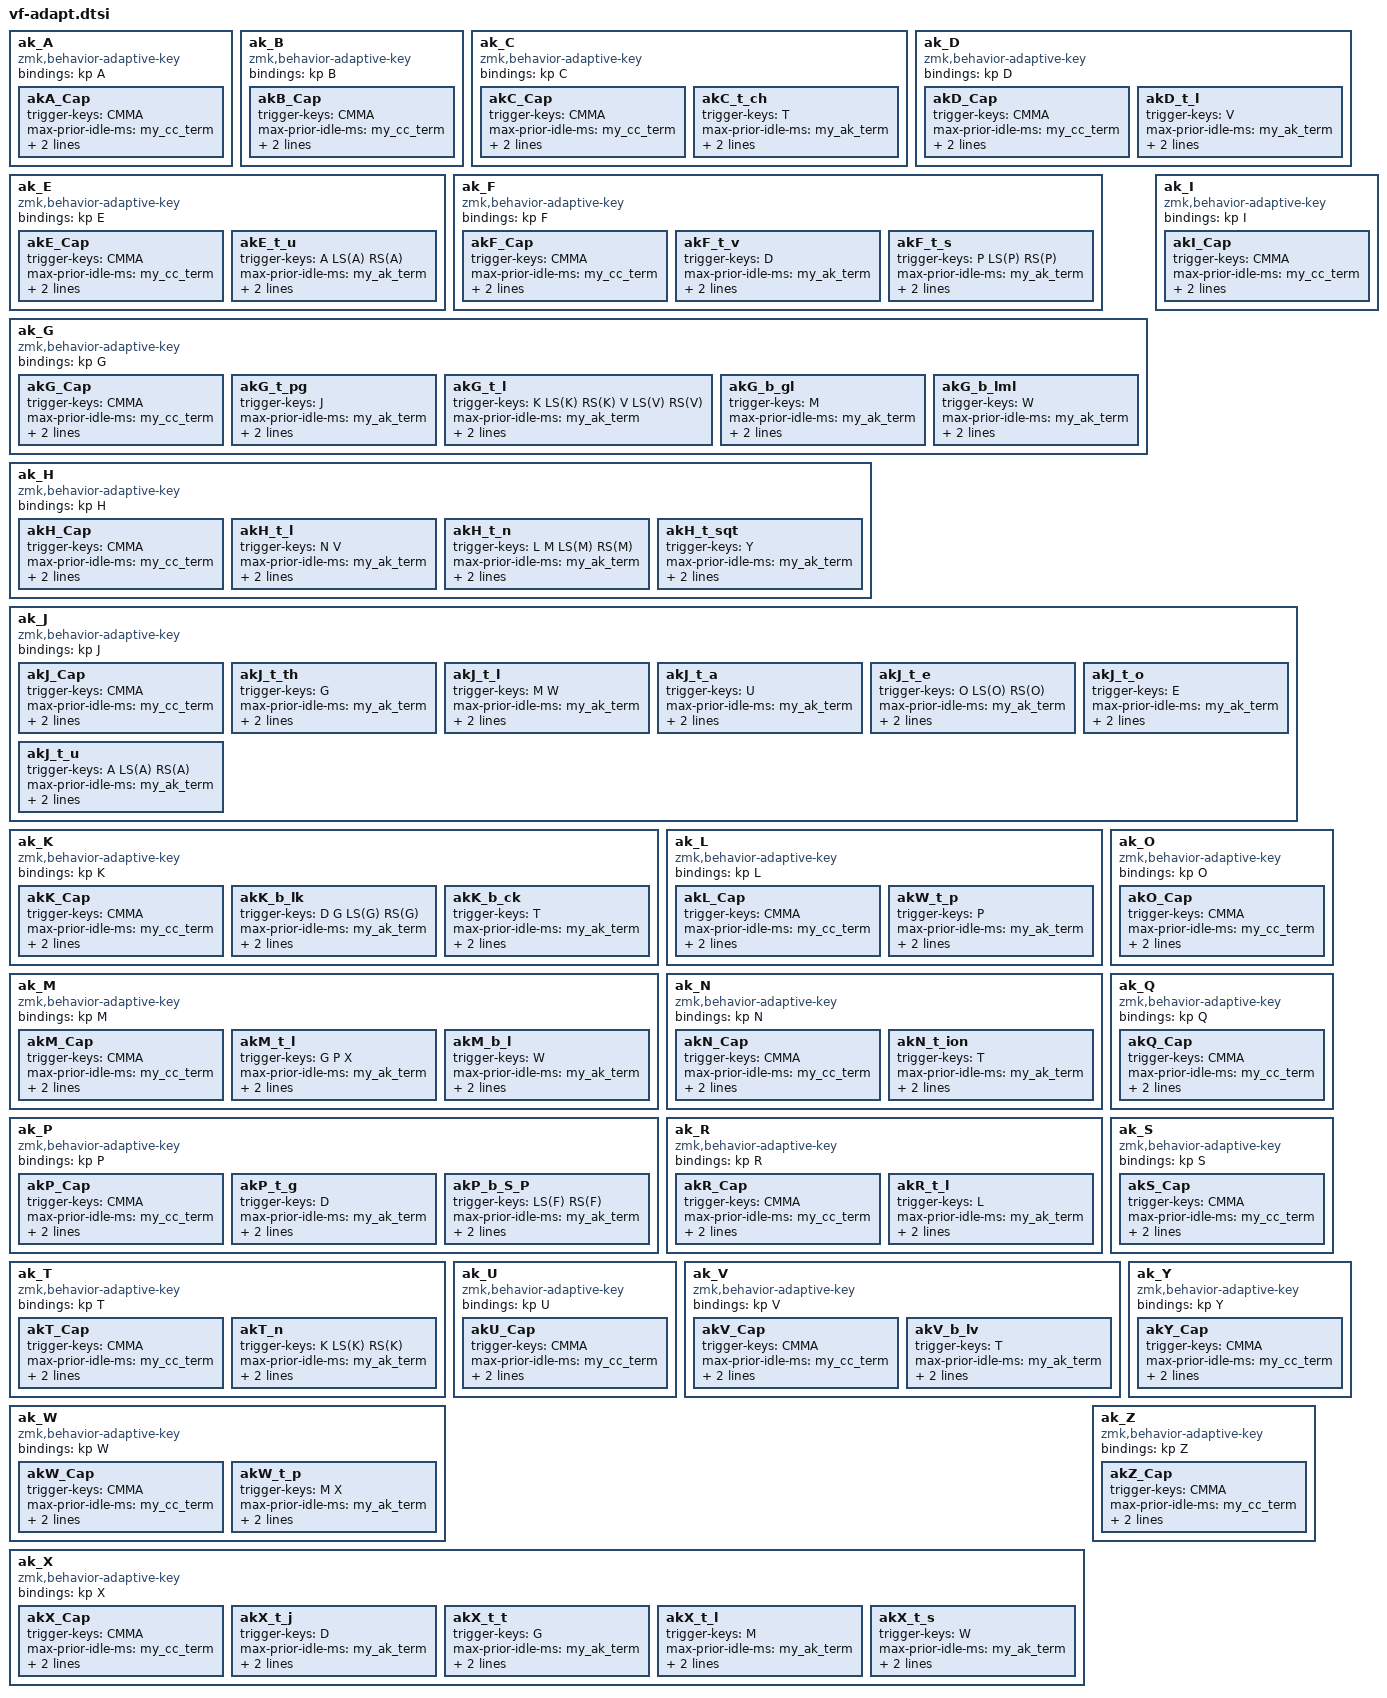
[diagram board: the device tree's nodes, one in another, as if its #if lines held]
/*
 * vf-adapt.h
 *
 * SPDX-License-Identifier: MIT
 *
 * AdaptiveKey behaviors
 * (send a different behavior based on prior key)
 *
 * these rules are very dependant on the underlying alpha layout topography
 *
 * using urob's behavior-adaptive-key module (https://github.com/urob/zmk-adaptive-key/)
 *
 */
 
        ak_A: ak_A {
            compatible = "zmk,behavior-adaptive-key";
            #binding-cells = <0>;
            bindings = <&kp A>;

            akA_Cap { trigger-keys = <CMMA>; max-prior-idle-ms = <my_cc_term>; bindings = <&kp BSPC &kp LS(A)>; strict-modifiers; };
        };
        ak_B: ak_B {
            compatible = "zmk,behavior-adaptive-key";
            #binding-cells = <0>;
            bindings = <&kp B>;

            akB_Cap { trigger-keys = <CMMA>; max-prior-idle-ms = <my_cc_term>; bindings = <&kp BSPC &kp LS(B)>; strict-modifiers; };
        };
        ak_C: ak_C {
            compatible = "zmk,behavior-adaptive-key";
            #binding-cells = <0>;
            bindings = <&kp C>;

            akC_Cap { trigger-keys = <CMMA>; max-prior-idle-ms = <my_cc_term>; bindings = <&kp BSPC &kp LS(C)>; strict-modifiers; };
            akC_t_ch { trigger-keys = <T>; max-prior-idle-ms = <my_ak_term>; bindings = <&kp C &kp H>; strict-modifiers; };
        };
        ak_D: ak_D {
            compatible = "zmk,behavior-adaptive-key";
            #binding-cells = <0>;
            bindings = <&kp D>;

            akD_Cap { trigger-keys = <CMMA>; max-prior-idle-ms = <my_cc_term>; bindings = <&kp BSPC &kp LS(D)>; strict-modifiers; };
            akD_t_l { trigger-keys = <V>; max-prior-idle-ms = <my_ak_term>; bindings = <&kp L>; strict-modifiers; };
        };
        ak_E: ak_E {
            compatible = "zmk,behavior-adaptive-key";
            #binding-cells = <0>;
            bindings = <&kp E>;

            akE_Cap { trigger-keys = <CMMA>; max-prior-idle-ms = <my_cc_term>; bindings = <&kp BSPC &kp LS(E)>; strict-modifiers; };
#ifdef MagicJ
            akE_t_u { trigger-keys = <A LS(A) RS(A)>; max-prior-idle-ms = <my_ak_term>; bindings = <&kp U>; strict-modifiers; };
#endif // MagicJ
        };
        ak_F: ak_F {
            compatible = "zmk,behavior-adaptive-key";
            #binding-cells = <0>;
            bindings = <&kp F>;

            akF_Cap { trigger-keys = <CMMA>; max-prior-idle-ms = <my_cc_term>; bindings = <&kp BSPC &kp LS(F)>; strict-modifiers; };
            akF_t_v { trigger-keys = <D>; max-prior-idle-ms = <my_ak_term>; bindings = <&kp V>; strict-modifiers; };
            akF_t_s { trigger-keys = <P LS(P) RS(P)>; max-prior-idle-ms = <my_ak_term>; bindings = <&kp S>; strict-modifiers; };
        };
        ak_G: ak_G {
            compatible = "zmk,behavior-adaptive-key";
            #binding-cells = <0>;
            bindings = <&kp G>;

            akG_Cap { trigger-keys = <CMMA>; max-prior-idle-ms = <my_cc_term>; bindings = <&kp BSPC &kp LS(G)>; strict-modifiers; };
            akG_t_pg { trigger-keys = <J>; max-prior-idle-ms = <my_ak_term>; bindings = <&kp P &kp G>; strict-modifiers; };
            akG_t_l  { trigger-keys = <K LS(K) RS(K) V LS(V) RS(V)>; max-prior-idle-ms = <my_ak_term>; bindings = <&kp L>; strict-modifiers; };
            akG_b_gl { trigger-keys = <M>; max-prior-idle-ms = <my_ak_term>; bindings = <&kp BSPC &kp L &kp G>; strict-modifiers; };
            akG_b_lml { trigger-keys = <W>; max-prior-idle-ms = <my_ak_term>; bindings = <&kp BSPC &kp L &kp M &kp L>; strict-modifiers; };
        };
        ak_H: ak_H {
            compatible = "zmk,behavior-adaptive-key";
            #binding-cells = <0>;
            bindings = <&kp H>;

            akH_Cap { trigger-keys = <CMMA>; max-prior-idle-ms = <my_cc_term>; bindings = <&kp BSPC &kp LS(H)>; strict-modifiers; };
            akH_t_l { trigger-keys = <N V>; max-prior-idle-ms = <my_ak_term>; bindings = <&kp L>; strict-modifiers; };
            akH_t_n { trigger-keys = <L M LS(M) RS(M)>; max-prior-idle-ms = <my_ak_term>; bindings = <&kp N>; strict-modifiers; };
            akH_t_sqt { trigger-keys = <Y>; max-prior-idle-ms = <my_ak_term>; bindings = <&kp SQT>; strict-modifiers; };
#ifdef MagicH
//            akH_t_a { trigger-keys = <U LS(U) RS(U)>; max-prior-idle-ms = <my_ak_term>; bindings = <&kp A>; strict-modifiers; };
//            akH_t_e { trigger-keys = <O LS(O) RS(O)>; max-prior-idle-ms = <my_ak_term>; bindings = <&kp E>; strict-modifiers; };
//            akH_t_o { trigger-keys = <E LS(E) RS(E)>; max-prior-idle-ms = <my_ak_term>; bindings = <&kp O>; strict-modifiers; };
//            akH_t_u { trigger-keys = <A LS(A) RS(A)>; max-prior-idle-ms = <my_ak_term>; bindings = <&kp U>; strict-modifiers; };
#endif // MagicH
        };
        ak_I: ak_I {
            compatible = "zmk,behavior-adaptive-key";
            #binding-cells = <0>;
            bindings = <&kp I>;

            akI_Cap { trigger-keys = <CMMA>; max-prior-idle-ms = <my_cc_term>; bindings = <&kp BSPC &kp LS(I)>; strict-modifiers; };
        };
        ak_J: ak_J {
            compatible = "zmk,behavior-adaptive-key";
            #binding-cells = <0>;
            bindings = <&kp J>;

            akJ_Cap { trigger-keys = <CMMA>; max-prior-idle-ms = <my_cc_term>; bindings = <&kp BSPC &kp LS(J)>; strict-modifiers; };
            akJ_t_th { trigger-keys = <G>; max-prior-idle-ms = <my_ak_term>; bindings = <&kp T &kp H>; strict-modifiers; strict-modifiers; };
            akJ_t_l { trigger-keys = <M W>; max-prior-idle-ms = <my_ak_term>; bindings = <&kp L>; strict-modifiers; strict-modifiers; };
/*
 * explore using J as a magic key like H for the four vowel SFBs
 *
 */
            akJ_t_a { trigger-keys = <U>; max-prior-idle-ms = <my_ak_term>; bindings = <&kp A>; strict-modifiers; strict-modifiers; };
            akJ_t_e { trigger-keys = <O LS(O) RS(O)>; max-prior-idle-ms = <my_ak_term>; bindings = <&kp E>; strict-modifiers; strict-modifiers; };
            akJ_t_o { trigger-keys = <E>; max-prior-idle-ms = <my_ak_term>; bindings = <&kp O>; strict-modifiers; strict-modifiers; };
            akJ_t_u { trigger-keys = <A LS(A) RS(A)>; max-prior-idle-ms = <my_ak_term>; bindings = <&kp U>; strict-modifiers; strict-modifiers; };

        };
        ak_K: ak_K {
            compatible = "zmk,behavior-adaptive-key";
            #binding-cells = <0>;
            bindings = <&kp K>;

            akK_Cap { trigger-keys = <CMMA>; max-prior-idle-ms = <my_cc_term>; bindings = <&kp BSPC &kp LS(K)>; strict-modifiers; };
            akK_b_lk { trigger-keys = <D G LS(G) RS(G)>; max-prior-idle-ms = <my_ak_term>; bindings = <&kp BSPC &kp L &kp K>; strict-modifiers; };
            akK_b_ck { trigger-keys = <T>; max-prior-idle-ms = <my_ak_term>; bindings = <&kp BSPC &kp C &kp K>; strict-modifiers; };
        };
        ak_L: ak_L {
            compatible = "zmk,behavior-adaptive-key";
            #binding-cells = <0>;
            bindings = <&kp L>;

            akL_Cap { trigger-keys = <CMMA>; max-prior-idle-ms = <my_cc_term>; bindings = <&kp BSPC &kp LS(L)>; strict-modifiers; };
            akW_t_p { trigger-keys = <P>; max-prior-idle-ms = <my_ak_term>; bindings = <&sl_L>; strict-modifiers; };
        };
        ak_M: ak_M {
            compatible = "zmk,behavior-adaptive-key";
            #binding-cells = <0>;
            bindings = <&kp M>;

            akM_Cap { trigger-keys = <CMMA>; max-prior-idle-ms = <my_cc_term>; bindings = <&kp BSPC &kp LS(M)>; strict-modifiers; };
            akM_t_l { trigger-keys = <G P X>; max-prior-idle-ms = <my_ak_term>; bindings = <&kp L>; strict-modifiers; };
            akM_b_l { trigger-keys = <W>; max-prior-idle-ms = <my_ak_term>; bindings = <&kp BSPC &kp L &sl_M>; strict-modifiers; };
        };
        ak_N: ak_N {
            compatible = "zmk,behavior-adaptive-key";
            #binding-cells = <0>;
            bindings = <&kp N>;

            akN_Cap { trigger-keys = <CMMA>; max-prior-idle-ms = <my_cc_term>; bindings = <&kp BSPC &kp LS(N)>; strict-modifiers; };
            akN_t_ion { trigger-keys = <T>; max-prior-idle-ms = <my_ak_term>; bindings = <&kp I &kp O &kp N>; strict-modifiers; };
        };
        ak_O: ak_O {
            compatible = "zmk,behavior-adaptive-key";
            #binding-cells = <0>;
            bindings = <&kp O>;

            akO_Cap { trigger-keys = <CMMA>; max-prior-idle-ms = <my_cc_term>; bindings = <&kp BSPC &kp LS(O)>; strict-modifiers; };
        };
        ak_P: ak_P {
            compatible = "zmk,behavior-adaptive-key";
            #binding-cells = <0>;
            bindings = <&kp P>;

            akP_Cap { trigger-keys = <CMMA>; max-prior-idle-ms = <my_cc_term>; bindings = <&kp BSPC &kp LS(P)>; strict-modifiers; };
            akP_t_g { trigger-keys = <D>; max-prior-idle-ms = <my_ak_term>; bindings = <&kp G>; strict-modifiers; };
            akP_b_S_P { trigger-keys = <LS(F) RS(F)>; max-prior-idle-ms = <my_ak_term>; bindings = <&kp BSPC &kp LS(S) &kp P>; strict-modifiers; };
        };
        ak_Q: ak_Q {
            compatible = "zmk,behavior-adaptive-key";
            #binding-cells = <0>;
            bindings = <&kp Q>;

            akQ_Cap { trigger-keys = <CMMA>; max-prior-idle-ms = <my_cc_term>; bindings = <&kp BSPC &kp LS(Q)>; strict-modifiers; };
        };
        ak_R: ak_R {
            compatible = "zmk,behavior-adaptive-key";
            #binding-cells = <0>;
            bindings = <&kp R>;

            akR_Cap { trigger-keys = <CMMA>; max-prior-idle-ms = <my_cc_term>; bindings = <&kp BSPC &kp LS(R)>; strict-modifiers; };
            akR_t_l { trigger-keys = <L>; max-prior-idle-ms = <my_ak_term>; bindings = <&kp L>; strict-modifiers; };
        };
        ak_S: ak_S {
            compatible = "zmk,behavior-adaptive-key";
            #binding-cells = <0>;
            bindings = <&kp S>;

            akS_Cap { trigger-keys = <CMMA>; max-prior-idle-ms = <my_cc_term>; bindings = <&kp BSPC &kp LS(S)>; strict-modifiers; };
        };
        ak_T: ak_T {
            compatible = "zmk,behavior-adaptive-key";
            #binding-cells = <0>;
            bindings = <&kp T>;

            akT_Cap { trigger-keys = <CMMA>; max-prior-idle-ms = <my_cc_term>; bindings = <&kp BSPC &kp LS(T)>; strict-modifiers; };
            akT_n  { trigger-keys = <K LS(K) RS(K)>; max-prior-idle-ms = <my_ak_term>; bindings = <&kp N>; strict-modifiers; };
        };
        ak_U: ak_U {
            compatible = "zmk,behavior-adaptive-key";
            #binding-cells = <0>;
            bindings = <&kp U>;

            akU_Cap { trigger-keys = <CMMA>; max-prior-idle-ms = <my_cc_term>; bindings = <&kp BSPC &kp LS(U)>; strict-modifiers; };
        };
        ak_V: ak_V {
            compatible = "zmk,behavior-adaptive-key";
            #binding-cells = <0>;
            bindings = <&kp V>;

            akV_Cap { trigger-keys = <CMMA>; max-prior-idle-ms = <my_cc_term>; bindings = <&kp BSPC &kp LS(V)>; strict-modifiers; };
            akV_b_lv { trigger-keys = <T>; max-prior-idle-ms = <my_ak_term>; bindings = <&kp BSPC &kp L &kp V>; strict-modifiers; };
        };
        ak_W: ak_W {
            compatible = "zmk,behavior-adaptive-key";
            #binding-cells = <0>;
            bindings = <&kp W>;

            akW_Cap { trigger-keys = <CMMA>; max-prior-idle-ms = <my_cc_term>; bindings = <&kp BSPC &kp LS(W)>; strict-modifiers; };
            akW_t_p { trigger-keys = <M X>; max-prior-idle-ms = <my_ak_term>; bindings = <&sl_P>; strict-modifiers; };
        };
        ak_X: ak_X {
            compatible = "zmk,behavior-adaptive-key";
            #binding-cells = <0>;
            bindings = <&kp X>;

            akX_Cap { trigger-keys = <CMMA>; max-prior-idle-ms = <my_cc_term>; bindings = <&kp BSPC &kp LS(X)>; strict-modifiers; };
            akX_t_j { trigger-keys = <D>; max-prior-idle-ms = <my_ak_term>; bindings = <&kp J>; strict-modifiers; };
            akX_t_t { trigger-keys = <G>; max-prior-idle-ms = <my_ak_term>; bindings = <&kp T>; strict-modifiers; };
            akX_t_l { trigger-keys = <M>; max-prior-idle-ms = <my_ak_term>; bindings = <&kp L>; strict-modifiers; };
            akX_t_s { trigger-keys = <W>; max-prior-idle-ms = <my_ak_term>; bindings = <&kp S>; strict-modifiers; };
        };
        ak_Y: ak_Y {
            compatible = "zmk,behavior-adaptive-key";
            #binding-cells = <0>;
            bindings = <&kp Y>;

            akY_Cap { trigger-keys = <CMMA>; max-prior-idle-ms = <my_cc_term>; bindings = <&kp BSPC &kp LS(Y)>; strict-modifiers; };
        };
        ak_Z: ak_Z {
            compatible = "zmk,behavior-adaptive-key";
            #binding-cells = <0>;
            bindings = <&kp Z>;

            akZ_Cap { trigger-keys = <CMMA>; max-prior-idle-ms = <my_cc_term>; bindings = <&kp BSPC &kp LS(Z)>; strict-modifiers; };
        };
